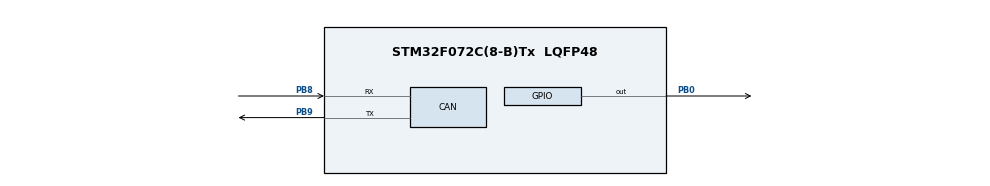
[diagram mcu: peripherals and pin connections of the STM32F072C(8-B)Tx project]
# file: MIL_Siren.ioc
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CAN.CalculateTimeQuantum=2000.0
Mcu.Family=STM32F0
Mcu.Name=STM32F072C(8-B)Tx
Mcu.Package=LQFP48
PB0.Signal=GPIO_Output
PB8.Mode=Master
PB8.Signal=CAN_RX
PB9.Mode=Master
PB9.Signal=CAN_TX
ProjectManager.HeapSize=0x200
ProjectManager.StackSize=0x400
ProjectManager.TargetToolchain=TrueSTUDIO
board=MIL_Siren

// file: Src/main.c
/*
 * Project: MIL Siren Board
 * Author: Marquez Jones
 * Desc: Currently receives CAN messages
 *
 */

#include "main.h"
#include "stm32f0xx_hal.h"

#define CANID 0xFF
#define FiltID 0x01
#define FiltIDLow 0x0000
#define FiltMaskIdHigh 0xFFFF //specifying which bits of the identifier
#define FiltMaskIdLow 0xFFFF  //are handled as “must match” (1) or as “don’t care” (0).
#define debug 1

CAN_HandleTypeDef hcan;
CanTxMsgTypeDef TxMessage;
CanRxMsgTypeDef RxMessage;
CAN_FilterConfTypeDef rxFilter;
char *CanReception;

/* USER CODE BEGIN PV */
/* Private variables ---------------------------------------------------------*/

/* USER CODE END PV */

void SystemClock_Config(void);
static void MX_GPIO_Init(void);
static void MX_CAN_Init(void);
void CanSetup(void);

/* USER CODE BEGIN PFP */
/* Private function prototypes -----------------------------------------------*/

/* USER CODE END PFP */

int main(void)
{

  /* MCU Configuration----------------------------------------------------------*/

  /* Reset of all peripherals, Initializes the Flash interface and the Systick. */
  HAL_Init();

  /* Configure the system clock */
  SystemClock_Config();

  /* Initialize all configured peripherals */
  MX_GPIO_Init();
  MX_CAN_Init();
  /* sUSER CODE BEGIN 2 */

  /* USER CODE END 2 */

  /* Infinite loop */
  /* USER CODE BEGIN WHILE */

  volatile uint8_t test1[8];
  uint8_t fmi;

  while (1)
  {

  /* USER CODE END WHILE */
//	  for (int i = 0; i < 8; i++) {
//		  hcan.pTxMsg->Data[i] = 0x00;
//	  }
//	  if (HAL_CAN_Transmit(&hcan, 30) != HAL_OK) {
//		  Error_Handler();
//	  }
//	  HAL_Delay(10);

	  //TEST RECEPTION CODE
	  if (HAL_CAN_Receive(&hcan, CAN_FIFO0, 30) == HAL_OK) {
		  for (int i = 0; i < 8; i++) {
			  test1[i] = hcan.pRxMsg->Data[i];
			  fmi = hcan.pRxMsg->FMI;
		  }
	  }
	  asm(" nop");

//	  if(test1[1] == 0x55){
//
//		  HAL_GPIO_WritePin(GPIOB, GPIO_PIN_0, GPIO_PIN_SET);
//		  HAL_Delay(1000);
//		  HAL_GPIO_WritePin(GPIOB, GPIO_PIN_0, GPIO_PIN_RESET);
//		  HAL_Delay(1000);
//
//	  }

  }

}

void SystemClock_Config(void)
{

  RCC_OscInitTypeDef RCC_OscInitStruct;
  RCC_ClkInitTypeDef RCC_ClkInitStruct;

    /**Initializes the CPU, AHB and APB busses clocks
    */
  RCC_OscInitStruct.OscillatorType = RCC_OSCILLATORTYPE_HSI;
  RCC_OscInitStruct.HSIState = RCC_HSI_ON;
  RCC_OscInitStruct.HSICalibrationValue = 16;
  RCC_OscInitStruct.PLL.PLLState = RCC_PLL_NONE;
  if (HAL_RCC_OscConfig(&RCC_OscInitStruct) != HAL_OK)
  {
    _Error_Handler(__FILE__, __LINE__);
  }

    /**Initializes the CPU, AHB and APB busses clocks
    */
  RCC_ClkInitStruct.ClockType = RCC_CLOCKTYPE_HCLK|RCC_CLOCKTYPE_SYSCLK
                              |RCC_CLOCKTYPE_PCLK1;
  RCC_ClkInitStruct.SYSCLKSource = RCC_SYSCLKSOURCE_HSI;
  RCC_ClkInitStruct.AHBCLKDivider = RCC_SYSCLK_DIV1;
  RCC_ClkInitStruct.APB1CLKDivider = RCC_HCLK_DIV1;

  if (HAL_RCC_ClockConfig(&RCC_ClkInitStruct, FLASH_LATENCY_0) != HAL_OK)
  {
    _Error_Handler(__FILE__, __LINE__);
  }

    /**Configure the Systick interrupt time 222
    */
  HAL_SYSTICK_Config(HAL_RCC_GetHCLKFreq()/1000);

    /**Configure the Systick
    */
  HAL_SYSTICK_CLKSourceConfig(SYSTICK_CLKSOURCE_HCLK);

  /* SysTick_IRQn interrupt configuration */
  HAL_NVIC_SetPriority(SysTick_IRQn, 0, 0);
}

/* CAN init function */
static void MX_CAN_Init(void)
{

  hcan.Instance = CAN;
  hcan.Init.Prescaler = 6;
  hcan.Init.Mode = CAN_MODE_NORMAL;
  hcan.Init.SJW = CAN_SJW_1TQ;
  hcan.Init.BS1 = CAN_BS1_6TQ;
  hcan.Init.BS2 = CAN_BS2_1TQ;
  hcan.Init.TTCM = DISABLE;
  hcan.Init.ABOM = ENABLE;
  hcan.Init.AWUM = ENABLE;
  hcan.Init.NART = DISABLE;
  hcan.Init.RFLM = DISABLE;
  hcan.Init.TXFP = DISABLE;
  CanSetup();
  if (HAL_CAN_Init(&hcan) != HAL_OK)
  {
    _Error_Handler(__FILE__, __LINE__);
  }

}
void CanSetup(void) {
	if (debug) {
		hcan.Instance->MCR = 0x60;
	}

	if (HAL_CAN_Init(&hcan) != HAL_OK) {
		_Error_Handler(__FILE__, __LINE__);
	}

	hcan.pTxMsg = &TxMessage;
	hcan.pRxMsg = &RxMessage;

	/*##-2- Configure the CAN Filter ###########################################*/
	rxFilter.FilterNumber = 2;
	rxFilter.FilterMode =  CAN_FILTERMODE_IDMASK;
	rxFilter.FilterScale = CAN_FILTERSCALE_32BIT;
	rxFilter.FilterIdHigh = FiltID << 5;
	rxFilter.FilterIdLow  = 0;
	rxFilter.FilterMaskIdHigh = 0xFFFF;
	rxFilter.FilterMaskIdLow  = 0xFFFF ;
	rxFilter.FilterFIFOAssignment = 0;
	rxFilter.FilterActivation = ENABLE;
	rxFilter.BankNumber = 1;

	if (HAL_CAN_ConfigFilter(&hcan, &rxFilter) != HAL_OK) {
		/* Filter configuration Error */
		Error_Handler();
	}

	hcan.pRxMsg->StdId = CANID;
	hcan.pRxMsg->ExtId = 0x00;
	hcan.pRxMsg->RTR = CAN_RTR_DATA;
	hcan.pRxMsg->IDE = CAN_ID_STD;
	//hcan.pRxMsg->DLC = 1;
	hcan.pRxMsg->FIFONumber = CAN_FIFO0;
	//hcan.pRxMsg->Data[0] = 0;
}

/** Configure pins as
        * Analog
        * Input
        * Output
        * EVENT_OUT
        * EXTI
*/
static void MX_GPIO_Init(void)
{

  GPIO_InitTypeDef GPIO_InitStruct;

  /* GPIO Ports Clock Enable */
  __HAL_RCC_GPIOB_CLK_ENABLE();

  /*Configure GPIO pin Output Level */
  HAL_GPIO_WritePin(GPIOB, GPIO_PIN_0, GPIO_PIN_RESET);

  /*Configure GPIO pin : PB0 */
  GPIO_InitStruct.Pin = GPIO_PIN_0;
  GPIO_InitStruct.Mode = GPIO_MODE_OUTPUT_PP;
  GPIO_InitStruct.Pull = GPIO_NOPULL;
  GPIO_InitStruct.Speed = GPIO_SPEED_FREQ_LOW;
  HAL_GPIO_Init(GPIOB, &GPIO_InitStruct);

}

void _Error_Handler(char *file, int line)
{
  /* USER CODE BEGIN Error_Handler_Debug */
  /* User can add his own implementation to report the HAL error return state */
//  while(1)
//  {
//  }
  /* USER CODE END Error_Handler_Debug */
}

/************************ (C) COPYRIGHT STMicroelectronics *****END OF FILE****/
